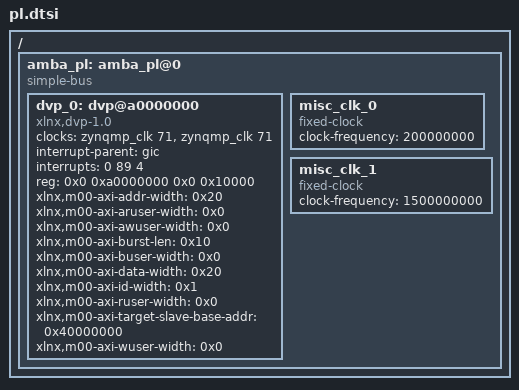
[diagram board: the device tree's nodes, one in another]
/*
 * CAUTION: This file is automatically generated by Xilinx.
 * Version:  
 * Today is: Fri Mar 24 05:07:09 2023
 */


/ {
	amba_pl: amba_pl@0 {
		#address-cells = <2>;
		#size-cells = <2>;
		compatible = "simple-bus";
		ranges ;
		dvp_0: dvp@a0000000 {
			clock-names = "s00_axi_aclk", "m00_axi_aclk";
			clocks = <&zynqmp_clk 71>, <&zynqmp_clk 71>;
			compatible = "xlnx,dvp-1.0";
			interrupt-names = "intr";
			interrupt-parent = <&gic>;
			interrupts = <0 89 4>;
			reg = <0x0 0xa0000000 0x0 0x10000>;
			xlnx,m00-axi-addr-width = <0x20>;
			xlnx,m00-axi-aruser-width = <0x0>;
			xlnx,m00-axi-awuser-width = <0x0>;
			xlnx,m00-axi-burst-len = <0x10>;
			xlnx,m00-axi-buser-width = <0x0>;
			xlnx,m00-axi-data-width = <0x20>;
			xlnx,m00-axi-id-width = <0x1>;
			xlnx,m00-axi-ruser-width = <0x0>;
			xlnx,m00-axi-target-slave-base-addr = <0x40000000>;
			xlnx,m00-axi-wuser-width = <0x0>;
		};
		misc_clk_0: misc_clk_0 {
			#clock-cells = <0>;
			clock-frequency = <200000000>;
			compatible = "fixed-clock";
		};
		misc_clk_1: misc_clk_1 {
			#clock-cells = <0>;
			clock-frequency = <1500000000>;
			compatible = "fixed-clock";
		};
	};
};
